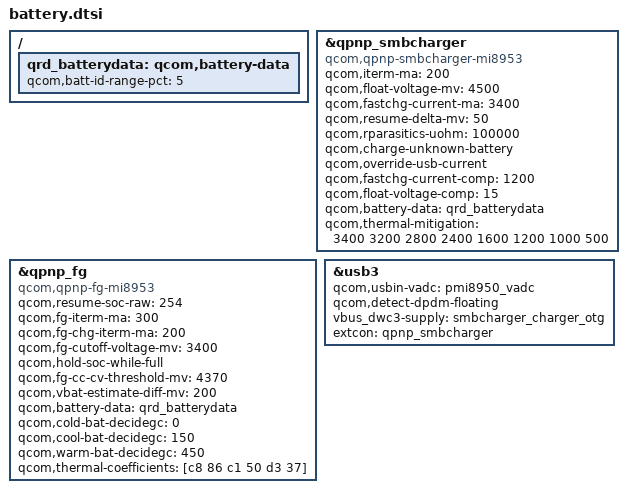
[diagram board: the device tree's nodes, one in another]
/{
	qrd_batterydata: qcom,battery-data {
		qcom,batt-id-range-pct = <5>;
		#include "../common/batterydata/Vince-sunwoda-40Kohm-4000mah.dtsi"
		#include "../common/batterydata/Vince-desay-24Kohm-4000mAh.dtsi"
		#include "../common/batterydata/Vince-coslight-50Kohm-4000mah.dtsi"
		/delete-node/ qcom,qrd_msm8937_sku1_2920mah;
	};
};

&qpnp_smbcharger {
	compatible = "qcom,qpnp-smbcharger-mi8953";
	qcom,iterm-ma = <200>;
	qcom,float-voltage-mv = <4500>;
	qcom,fastchg-current-ma = <3400>;
	qcom,resume-delta-mv = <50>;
	/delete-property/ qcom,rparasitic-uohm;
	qcom,rparasitics-uohm = <100000>;
	qcom,charge-unknown-battery;
	/delete-property/ qcom,parallel-usb-min-current-ma;
	/delete-property/ qcom,parallel-usb-9v-min-current-ma;
	/delete-property/ qcom,parallel-allowed-lowering-ma;
	qcom,override-usb-current;
	qcom,fastchg-current-comp = <1200>;
	qcom,float-voltage-comp = <15>;
	/delete-property/ qcom,autoadjust-vfloat;
	/delete-property/ qcom,chg-led-sw-controls;
	/delete-property/ qcom,chg-led-support;
	/delete-property/ qcom,external-typec;
	/delete-property/ qcom,typec-psy-name;
	qcom,battery-data = <&qrd_batterydata>;
	qcom,thermal-mitigation = <3400 3200 2800 2400 1600 1200 1000 500>;
};

&qpnp_fg {
	compatible = "qcom,qpnp-fg-mi8953";
	/delete-property/ qcom,resume-soc;
	qcom,resume-soc-raw = <254>;
	qcom,fg-iterm-ma = <300>;
	qcom,fg-chg-iterm-ma = <200>;
	qcom,fg-cutoff-voltage-mv = <3400>;
	qcom,hold-soc-while-full;
	qcom,fg-cc-cv-threshold-mv =<4370>;
	qcom,vbat-estimate-diff-mv = <200>;
	qcom,battery-data = <&qrd_batterydata>;
	qcom,cold-bat-decidegc = <0>;
	qcom,cool-bat-decidegc = <150>;
	qcom,warm-bat-decidegc = <450>;
	qcom,thermal-coefficients = [c8 86 c1 50 d3 37];
};

&usb3 {
	qcom,usbin-vadc = <&pmi8950_vadc>;
	qcom,detect-dpdm-floating;
	vbus_dwc3-supply = <&smbcharger_charger_otg>;
	extcon = <&qpnp_smbcharger>;
};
